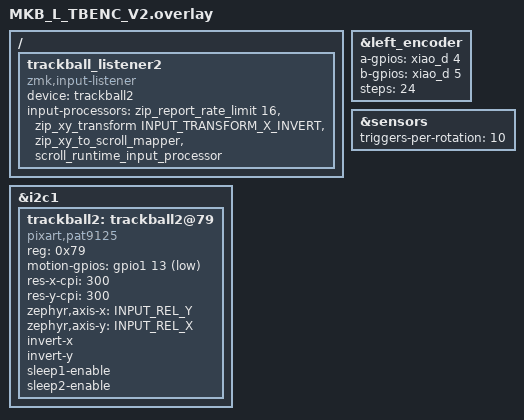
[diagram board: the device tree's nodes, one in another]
#include <input/processors/report_rate_limit.dtsi>

/* TBENC V2: PAT9125 motion on P1.13 (gpio1 13, module-debugger準拠).
 * EC11はP1.13との衝突を避けるためD4/D5 (P0.04/P0.05) へ移動。
 * 使用可能GPIO: P0.04(D4), P0.05(D5), P1.12(D7), P1.13(D8)
 *   - P1.13: PAT9125 motion interrupt
 *   - P1.12: 未使用 (必要に応じて追加)
 *   - P0.04: EC11 A-phase
 *   - P0.05: EC11 B-phase
 */

&left_encoder {
    a-gpios = <&xiao_d 4 (GPIO_ACTIVE_HIGH | GPIO_PULL_UP)>;
    b-gpios = <&xiao_d 5 (GPIO_ACTIVE_HIGH | GPIO_PULL_UP)>;
    steps = <24>;
    status = "okay";
};

&sensors {
    triggers-per-rotation = <10>;
};

/ {
    trackball_listener2: trackball_listener2 {
        compatible = "zmk,input-listener";
        device = <&trackball2>;
        status = "okay";
        input-processors = <&zip_report_rate_limit 16>,
                           <&zip_xy_transform INPUT_TRANSFORM_X_INVERT>,
                           <&zip_xy_to_scroll_mapper &scroll_runtime_input_processor>;
    };
};

&i2c1 {
    status = "okay";

    trackball2: trackball2@79 {
        status = "okay";
        compatible = "pixart,pat9125";
        reg = <0x79>; /* HIGH:0x73, LOW:0x75, NC:0x79 */
        motion-gpios = <&gpio1 13 (GPIO_ACTIVE_LOW | GPIO_PULL_UP)>;
        res-x-cpi = <300>;
        res-y-cpi = <300>;
        zephyr,axis-x = <INPUT_REL_Y>;
        zephyr,axis-y = <INPUT_REL_X>;
        invert-x;
        invert-y;
        sleep1-enable;
        sleep2-enable;
    };
};
